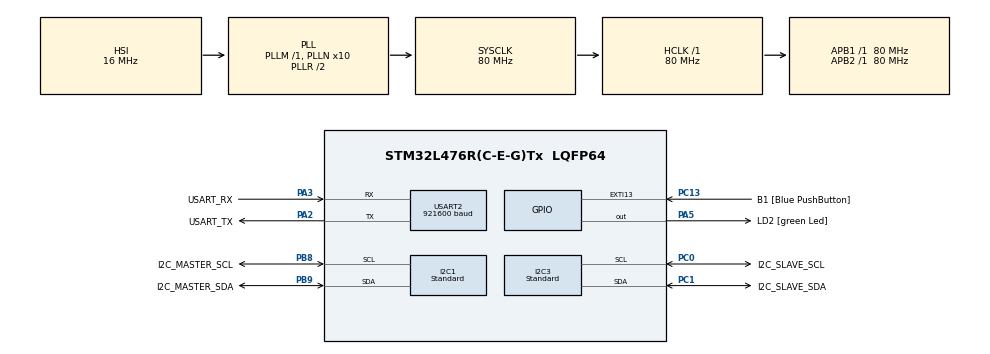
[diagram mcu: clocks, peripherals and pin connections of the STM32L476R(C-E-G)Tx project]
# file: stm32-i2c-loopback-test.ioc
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Dma.I2C1_RX.1.Direction=DMA_PERIPH_TO_MEMORY
Dma.I2C1_RX.1.Instance=DMA2_Channel6
Dma.I2C1_RX.1.MemDataAlignment=DMA_MDATAALIGN_BYTE
Dma.I2C1_RX.1.MemInc=DMA_MINC_ENABLE
Dma.I2C1_RX.1.Mode=DMA_NORMAL
Dma.I2C1_RX.1.PeriphDataAlignment=DMA_PDATAALIGN_BYTE
Dma.I2C1_RX.1.PeriphInc=DMA_PINC_DISABLE
Dma.I2C1_RX.1.Priority=DMA_PRIORITY_LOW
Dma.I2C1_TX.2.Direction=DMA_MEMORY_TO_PERIPH
Dma.I2C1_TX.2.Instance=DMA1_Channel6
Dma.I2C1_TX.2.MemDataAlignment=DMA_MDATAALIGN_BYTE
Dma.I2C1_TX.2.MemInc=DMA_MINC_ENABLE
Dma.I2C1_TX.2.Mode=DMA_NORMAL
Dma.I2C1_TX.2.PeriphDataAlignment=DMA_PDATAALIGN_BYTE
Dma.I2C1_TX.2.PeriphInc=DMA_PINC_DISABLE
Dma.I2C1_TX.2.Priority=DMA_PRIORITY_LOW
Dma.I2C3_RX.3.Direction=DMA_PERIPH_TO_MEMORY
Dma.I2C3_RX.3.Instance=DMA1_Channel3
Dma.I2C3_RX.3.MemDataAlignment=DMA_MDATAALIGN_BYTE
Dma.I2C3_RX.3.MemInc=DMA_MINC_ENABLE
Dma.I2C3_RX.3.Mode=DMA_NORMAL
Dma.I2C3_RX.3.PeriphDataAlignment=DMA_PDATAALIGN_BYTE
Dma.I2C3_RX.3.PeriphInc=DMA_PINC_DISABLE
Dma.I2C3_RX.3.Priority=DMA_PRIORITY_MEDIUM
Dma.Request0=USART2_TX
Dma.Request1=I2C1_RX
Dma.Request2=I2C1_TX
Dma.Request3=I2C3_RX
Dma.USART2_TX.0.Direction=DMA_MEMORY_TO_PERIPH
Dma.USART2_TX.0.Instance=DMA1_Channel7
Dma.USART2_TX.0.MemDataAlignment=DMA_MDATAALIGN_BYTE
Dma.USART2_TX.0.MemInc=DMA_MINC_ENABLE
Dma.USART2_TX.0.Mode=DMA_NORMAL
Dma.USART2_TX.0.PeriphDataAlignment=DMA_PDATAALIGN_BYTE
Dma.USART2_TX.0.PeriphInc=DMA_PINC_DISABLE
Dma.USART2_TX.0.Priority=DMA_PRIORITY_LOW
FREERTOS.Tasks01=I2cMasterTask,24,1200,StartI2cMasterTask,As weak,NULL,Static,I2cMasterTaskBuffer,I2cMasterTaskControlBlock;I2cSlaveTask,24,1200,StartI2cSlaveTask,As weak,NULL,Static,I2cSlaveTaskBuffer,I2cSlaveTaskControlBlock;UsbSendTask,8,2000,StartUsbSendTask,As weak,NULL,Static,UsbSendTaskBuffer,UsbSendTaskControlBlock
FREERTOS.configCHECK_FOR_STACK_OVERFLOW=2
FREERTOS.configENABLE_FPU=1
FREERTOS.configMINIMAL_STACK_SIZE=64
FREERTOS.configTOTAL_HEAP_SIZE=3000
FREERTOS.configUSE_DAEMON_TASK_STARTUP_HOOK=1
FREERTOS.configUSE_MALLOC_FAILED_HOOK=1
FREERTOS.configUSE_NEWLIB_REENTRANT=1
FREERTOS.configUSE_TICK_HOOK=1
I2C1.I2C_Speed_Mode=I2C_Standard
I2C1.OwnAddress=0
I2C1.Timing=0x10909CEC
I2C3.CustomTiming=Disabled
I2C3.I2C_Speed_Mode=I2C_Standard
I2C3.OwnAddress=(I2C_SLAVE_DEV_ADDR << 1)
I2C3.Timing=0x10909CEC
Mcu.Family=STM32L4
Mcu.Name=STM32L476R(C-E-G)Tx
Mcu.Package=LQFP64
Mcu.UserConstants=I2C_SLAVE_DEV_ADDR,0x11
NVIC.DMA1_Channel3_IRQn=true\:5\:0\:false\:false\:true\:true\:false\:true\:true
NVIC.DMA1_Channel6_IRQn=true\:5\:0\:false\:false\:true\:true\:false\:true\:true
NVIC.DMA1_Channel7_IRQn=true\:5\:0\:true\:false\:true\:true\:false\:true\:true
NVIC.DMA2_Channel6_IRQn=true\:5\:0\:false\:false\:true\:true\:false\:true\:true
NVIC.I2C1_ER_IRQn=true\:5\:0\:true\:false\:true\:true\:true\:true\:true
NVIC.I2C1_EV_IRQn=true\:5\:0\:true\:false\:true\:true\:true\:true\:true
NVIC.I2C3_ER_IRQn=true\:5\:0\:true\:false\:true\:true\:true\:true\:true
NVIC.I2C3_EV_IRQn=true\:5\:0\:true\:false\:true\:true\:true\:true\:true
NVIC.PriorityGroup=NVIC_PRIORITYGROUP_4
NVIC.TIM1_TRG_COM_TIM17_IRQn=true\:15\:0\:false\:false\:true\:false\:false\:true\:true
NVIC.TimeBase=TIM1_TRG_COM_TIM17_IRQn
NVIC.TimeBaseIP=TIM17
NVIC.USART2_IRQn=true\:5\:0\:true\:false\:true\:true\:true\:true\:true
PA13\ (JTMS-SWDIO).GPIO_Label=TMS
PA13\ (JTMS-SWDIO).Mode=Serial_Wire
PA13\ (JTMS-SWDIO).Signal=SYS_JTMS-SWDIO
PA14\ (JTCK-SWCLK).GPIO_Label=TCK
PA14\ (JTCK-SWCLK).Mode=Serial_Wire
PA14\ (JTCK-SWCLK).Signal=SYS_JTCK-SWCLK
PA2.GPIO_Label=USART_TX
PA2.GPIO_Mode=GPIO_MODE_AF_PP
PA2.GPIO_PuPd=GPIO_NOPULL
PA2.GPIO_Speed=GPIO_SPEED_FREQ_VERY_HIGH
PA2.Mode=Asynchronous
PA2.Signal=USART2_TX
PA3.GPIO_Label=USART_RX
PA3.GPIO_Mode=GPIO_MODE_AF_PP
PA3.GPIO_PuPd=GPIO_NOPULL
PA3.GPIO_Speed=GPIO_SPEED_FREQ_VERY_HIGH
PA3.Mode=Asynchronous
PA3.Signal=USART2_RX
PA5.GPIO_Label=LD2 [green Led]
PA5.GPIO_ModeDefaultOutputPP=GPIO_MODE_OUTPUT_PP
PA5.GPIO_PuPd=GPIO_NOPULL
PA5.GPIO_Speed=GPIO_SPEED_FREQ_LOW
PA5.Signal=GPIO_Output
PB3\ (JTDO-TRACESWO).GPIO_Label=SWO
PB3\ (JTDO-TRACESWO).Signal=SYS_JTDO-SWO
PB8.GPIO_Label=I2C_MASTER_SCL
PB8.GPIO_Pu=GPIO_PULLUP
PB8.GPIO_Speed=GPIO_SPEED_FREQ_VERY_HIGH
PB8.Mode=I2C
PB8.Signal=I2C1_SCL
PB9.GPIO_Label=I2C_MASTER_SDA
PB9.GPIO_Pu=GPIO_PULLUP
PB9.GPIO_Speed=GPIO_SPEED_FREQ_VERY_HIGH
PB9.Mode=I2C
PB9.Signal=I2C1_SDA
PC0.GPIO_Label=I2C_SLAVE_SCL
PC0.GPIO_Pu=GPIO_PULLUP
PC0.GPIO_Speed=GPIO_SPEED_FREQ_VERY_HIGH
PC0.Mode=I2C
PC0.Signal=I2C3_SCL
PC1.GPIO_Label=I2C_SLAVE_SDA
PC1.GPIO_Pu=GPIO_PULLUP
PC1.GPIO_Speed=GPIO_SPEED_FREQ_VERY_HIGH
PC1.Mode=I2C
PC1.Signal=I2C3_SDA
PC13.GPIO_Label=B1 [Blue PushButton]
PC13.GPIO_ModeDefaultEXTI=GPIO_MODE_IT_FALLING
PC13.GPIO_PuPd=GPIO_NOPULL
PC13.Signal=GPXTI13
PC14-OSC32_IN\ (PC14).Mode=LSE-External-Oscillator
PC14-OSC32_IN\ (PC14).Signal=RCC_OSC32_IN
PC15-OSC32_OUT\ (PC15).Mode=LSE-External-Oscillator
PC15-OSC32_OUT\ (PC15).Signal=RCC_OSC32_OUT
PH0-OSC_IN\ (PH0).Signal=RCC_OSC_IN
PH1-OSC_OUT\ (PH1).Signal=RCC_OSC_OUT
ProjectManager.HeapSize=0x200
ProjectManager.StackSize=0x400
ProjectManager.TargetToolchain=STM32CubeIDE
RCC.ADCFreq_Value=64000000
RCC.AHBFreq_Value=80000000
RCC.APB1Freq_Value=80000000
RCC.APB1TimFreq_Value=80000000
RCC.APB2Freq_Value=80000000
RCC.APB2TimFreq_Value=80000000
RCC.CortexFreq_Value=80000000
RCC.FLatency-AdvancedSettings=FLASH_LATENCY_0
RCC.HCLKFreq_Value=80000000
RCC.HSE_VALUE=8000000
RCC.HSI_VALUE=16000000
RCC.MSI_VALUE=4000000
RCC.PLLN=10
RCC.PLLSourceVirtual=RCC_PLLSOURCE_HSI
RCC.PREFETCH_ENABLE=1
RCC.SYSCLKFreq_VALUE=80000000
RCC.SYSCLKSource=RCC_SYSCLKSOURCE_PLLCLK
RCC.USBFreq_Value=64000000
RCC.VCOOutputFreq_Value=160000000
USART2.BaudRate=921600
USART2.VirtualMode-Asynchronous=VM_ASYNC
VP_FREERTOS_VS_CMSIS_V2.Mode=CMSIS_V2
VP_SYS_VS_tim17.Mode=TIM17
board=NUCLEO-L476RG

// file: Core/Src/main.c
/* USER CODE BEGIN Header */
/**
  ******************************************************************************
  * @file           : main.c
  * @brief          : Main program body
  ******************************************************************************
  * @attention
  *
  * Copyright (c) 2022 STMicroelectronics.
  * All rights reserved.
  *
  * This software is licensed under terms that can be found in the LICENSE file
  * in the root directory of this software component.
  * If no LICENSE file comes with this software, it is provided AS-IS.
  *
  ******************************************************************************
  */
/* USER CODE END Header */
#include "main.h"
#include "cmsis_os.h"
#include "dma.h"
#include "i2c.h"
#include "usart.h"
#include "gpio.h"

void SystemClock_Config(void);
void MX_FREERTOS_Init(void);

int main(void)
{

  /* MCU Configuration--------------------------------------------------------*/

  /* Reset of all peripherals, Initializes the Flash interface and the Systick. */
  HAL_Init();

  /* Configure the system clock */
  SystemClock_Config();

  /* Initialize all configured peripherals */
  MX_DMA_Init();
  MX_GPIO_Init();
  MX_USART2_UART_Init();
  MX_I2C1_Init();
  MX_I2C3_Init();

  /* Init scheduler */
  osKernelInitialize();  /* Call init function for freertos objects (in freertos.c) */
  MX_FREERTOS_Init();
  /* Start scheduler */
  osKernelStart();

  /* We should never get here as control is now taken by the scheduler */
  /* Infinite loop */
  while (1)
  {

  }
}

void SystemClock_Config(void)
{
  RCC_OscInitTypeDef RCC_OscInitStruct = {0};
  RCC_ClkInitTypeDef RCC_ClkInitStruct = {0};

  /** Configure the main internal regulator output voltage
  */
  if (HAL_PWREx_ControlVoltageScaling(PWR_REGULATOR_VOLTAGE_SCALE1) != HAL_OK)
  {
    Error_Handler();
  }
  /** Initializes the RCC Oscillators according to the specified parameters
  * in the RCC_OscInitTypeDef structure.
  */
  RCC_OscInitStruct.OscillatorType = RCC_OSCILLATORTYPE_HSI;
  RCC_OscInitStruct.HSIState = RCC_HSI_ON;
  RCC_OscInitStruct.HSICalibrationValue = RCC_HSICALIBRATION_DEFAULT;
  RCC_OscInitStruct.PLL.PLLState = RCC_PLL_ON;
  RCC_OscInitStruct.PLL.PLLSource = RCC_PLLSOURCE_HSI;
  RCC_OscInitStruct.PLL.PLLM = 1;
  RCC_OscInitStruct.PLL.PLLN = 10;
  RCC_OscInitStruct.PLL.PLLP = RCC_PLLP_DIV7;
  RCC_OscInitStruct.PLL.PLLQ = RCC_PLLQ_DIV2;
  RCC_OscInitStruct.PLL.PLLR = RCC_PLLR_DIV2;
  if (HAL_RCC_OscConfig(&RCC_OscInitStruct) != HAL_OK)
  {
    Error_Handler();
  }
  /** Initializes the CPU, AHB and APB buses clocks
  */
  RCC_ClkInitStruct.ClockType = RCC_CLOCKTYPE_HCLK|RCC_CLOCKTYPE_SYSCLK
                              |RCC_CLOCKTYPE_PCLK1|RCC_CLOCKTYPE_PCLK2;
  RCC_ClkInitStruct.SYSCLKSource = RCC_SYSCLKSOURCE_PLLCLK;
  RCC_ClkInitStruct.AHBCLKDivider = RCC_SYSCLK_DIV1;
  RCC_ClkInitStruct.APB1CLKDivider = RCC_HCLK_DIV1;
  RCC_ClkInitStruct.APB2CLKDivider = RCC_HCLK_DIV1;

  if (HAL_RCC_ClockConfig(&RCC_ClkInitStruct, FLASH_LATENCY_4) != HAL_OK)
  {
    Error_Handler();
  }
}

void HAL_TIM_PeriodElapsedCallback(TIM_HandleTypeDef *htim)
{
  if (htim->Instance == TIM17) {
    HAL_IncTick();
  }
}

void Error_Handler(void)
{
  __disable_irq();
  while (1)
  {
  }
}

#ifdef  USE_FULL_ASSERT
/**
  * @brief  Reports the name of the source file and the source line number
  *         where the assert_param error has occurred.
  * @param  file: pointer to the source file name
  * @param  line: assert_param error line source number
  * @retval None
  */
void assert_failed(uint8_t *file, uint32_t line)
{
  /* USER CODE BEGIN 6 */
  /* User can add his own implementation to report the file name and line number,
     ex: printf("Wrong parameters value: file %s on line %d\r\n", file, line) */
//	printf("Wrong parameters value: file %s on line %d\r\n", file, line);
//	static char strBuf[200];
//	sprintf(strBuf, "Wrong parameters value: file %s on line %d\n", file, line);
//	user_puts(strBuf);
  /* USER CODE END 6 */
}
#endif /* USE_FULL_ASSERT */

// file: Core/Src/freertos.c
/* USER CODE BEGIN Header */
/**
  ******************************************************************************
  * File Name          : freertos.c
  * Description        : Code for freertos applications
  ******************************************************************************
  * @attention
  *
  * Copyright (c) 2022 STMicroelectronics.
  * All rights reserved.
  *
  * This software is licensed under terms that can be found in the LICENSE file
  * in the root directory of this software component.
  * If no LICENSE file comes with this software, it is provided AS-IS.
  *
  ******************************************************************************
  */
/* USER CODE END Header */

#include "FreeRTOS.h"
#include "task.h"
#include "main.h"
#include "cmsis_os.h"

/* USER CODE BEGIN Includes */
#include <string.h>
#include "usart.h"
/* USER CODE END Includes */

typedef StaticTask_t osStaticThreadDef_t;

/* Definitions for I2cMasterTask */
osThreadId_t I2cMasterTaskHandle;
uint32_t I2cMasterTaskBuffer[ 1200 ];
osStaticThreadDef_t I2cMasterTaskControlBlock;
const osThreadAttr_t I2cMasterTask_attributes = {
  .name = "I2cMasterTask",
  .cb_mem = &I2cMasterTaskControlBlock,
  .cb_size = sizeof(I2cMasterTaskControlBlock),
  .stack_mem = &I2cMasterTaskBuffer[0],
  .stack_size = sizeof(I2cMasterTaskBuffer),
  .priority = (osPriority_t) osPriorityNormal,
};
/* Definitions for I2cSlaveTask */
osThreadId_t I2cSlaveTaskHandle;
uint32_t I2cSlaveTaskBuffer[ 1200 ];
osStaticThreadDef_t I2cSlaveTaskControlBlock;
const osThreadAttr_t I2cSlaveTask_attributes = {
  .name = "I2cSlaveTask",
  .cb_mem = &I2cSlaveTaskControlBlock,
  .cb_size = sizeof(I2cSlaveTaskControlBlock),
  .stack_mem = &I2cSlaveTaskBuffer[0],
  .stack_size = sizeof(I2cSlaveTaskBuffer),
  .priority = (osPriority_t) osPriorityNormal,
};
/* Definitions for UsbSendTask */
osThreadId_t UsbSendTaskHandle;
uint32_t UsbSendTaskBuffer[ 2000 ];
osStaticThreadDef_t UsbSendTaskControlBlock;
const osThreadAttr_t UsbSendTask_attributes = {
  .name = "UsbSendTask",
  .cb_mem = &UsbSendTaskControlBlock,
  .cb_size = sizeof(UsbSendTaskControlBlock),
  .stack_mem = &UsbSendTaskBuffer[0],
  .stack_size = sizeof(UsbSendTaskBuffer),
  .priority = (osPriority_t) osPriorityLow,
};

void StartI2cMasterTask(void *argument);
void StartI2cSlaveTask(void *argument);
void StartUsbSendTask(void *argument);

void MX_FREERTOS_Init(void); /* (MISRA C 2004 rule 8.1) */

/* Hook prototypes */
void vApplicationTickHook(void);
void vApplicationStackOverflowHook(xTaskHandle xTask, signed char *pcTaskName);
void vApplicationMallocFailedHook(void);
void vApplicationDaemonTaskStartupHook(void);

void MX_FREERTOS_Init(void) {

  /* Create the thread(s) */
  /* creation of I2cMasterTask */
  I2cMasterTaskHandle = osThreadNew(StartI2cMasterTask, NULL, &I2cMasterTask_attributes);

  /* creation of I2cSlaveTask */
  I2cSlaveTaskHandle = osThreadNew(StartI2cSlaveTask, NULL, &I2cSlaveTask_attributes);

  /* creation of UsbSendTask */
  UsbSendTaskHandle = osThreadNew(StartUsbSendTask, NULL, &UsbSendTask_attributes);

}

__weak void StartI2cMasterTask(void *argument)
{
  for(;;)
  {
    osDelay(1);
  }
}

__weak void StartI2cSlaveTask(void *argument)
{
  for(;;)
  {
    osDelay(1);
  }
}

__weak void StartUsbSendTask(void *argument)
{
  for(;;)
  {
    osDelay(1);
  }
}
